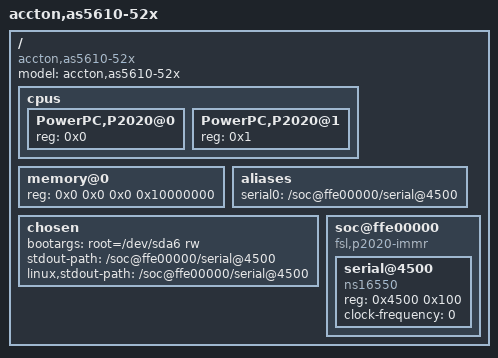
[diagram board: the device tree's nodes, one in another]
/*
 * Minimal device tree for P2020/AS5610-52X so FIT can be built.
 * Replace with ONL/Cumulus DTB for real boot. Compatible enough for kernel to accept.
 */
/dts-v1/;

/ {
	model = "accton,as5610-52x";
	compatible = "accton,as5610-52x", "fsl,P2020RDB";
	#address-cells = <2>;
	#size-cells = <2>;

	cpus {
		#address-cells = <1>;
		#size-cells = <0>;
		PowerPC,P2020@0 {
			device_type = "cpu";
			reg = <0x0>;
		};
		PowerPC,P2020@1 {
			device_type = "cpu";
			reg = <0x1>;
		};
	};

	memory@0 {
		device_type = "memory";
		reg = <0x0 0x0 0x0 0x10000000>;
	};

	/* U-Boot may resolve console from aliases; provide so path lookup succeeds */
	aliases {
		serial0 = "/soc@ffe00000/serial@4500";
	};

	chosen {
		bootargs = "root=/dev/sda6 rw";
		/* Both required: U-Boot 2013.01 sets linux,stdout-path and fails with FDT_ERR_NOTFOUND if path missing */
		stdout-path = "/soc@ffe00000/serial@4500";
		linux,stdout-path = "/soc@ffe00000/serial@4500";
	};

	/* P2020 IMMR at 0xffe00000; unit address must match so U-Boot can resolve chosen stdout-path */
	soc@ffe00000 {
		compatible = "fsl,p2020-immr", "simple-bus";
		#address-cells = <1>;
		#size-cells = <1>;
		ranges = <0x0 0xf 0xffe00000 0x200000>;

		serial@4500 {
			device_type = "serial";
			compatible = "ns16550";
			reg = <0x4500 0x100>;
			clock-frequency = <0>;
		};
	};
};
